# ATSAMD10D13A register map
Vendor: Atmel Corporation; Series: SAMD10; File version: A
CPU: CM0+ r0p1, little endian, no MPU, no FPU, VTOR, 2 interrupt priority bits
Registers are 32-bit, read-write, reset 0x0 unless marked. A register's access mark holds for its fields unless they carry their own. Offsets are from the block's base; [hi:lo] are bit positions; {n}, {i} and the like mark numbered series; 'fields as' and 'values as' point back to an identical list.

## DAC — Digital Analog Converter
Base 0x42002800; register names take the prefix DAC_
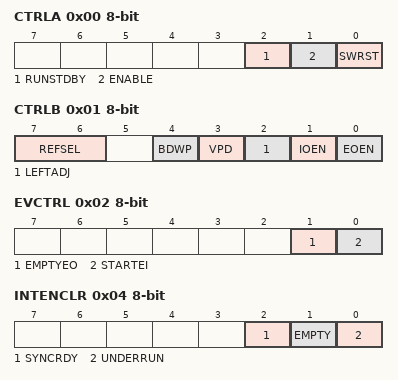
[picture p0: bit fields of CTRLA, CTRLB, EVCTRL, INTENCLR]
0x00 CTRLA 8-bit — Control A
  [2] RUNSTDBY — Run in Standby
  [1] ENABLE
  [0] SWRST — Software Reset
0x01 CTRLB 8-bit — Control B
  [7:6] REFSEL — Reference Selection
    0=INT1V (Internal 1.0V reference); 1=AVCC; 2=VREFP (External reference)
  [4] BDWP — Bypass DATABUF Write Protection
  [3] VPD — Voltage Pump Disable
  [2] LEFTADJ — Left Adjusted Data
  [1] IOEN — Internal Output Enable
  [0] EOEN — External Output Enable
0x02 EVCTRL 8-bit — Event Control
  [1] EMPTYEO — Data Buffer Empty Event Output
  [0] STARTEI — Start Conversion Event Input
0x04 INTENCLR 8-bit — Interrupt Enable Clear
  [2] SYNCRDY — Synchronization Ready Interrupt Enable
  [1] EMPTY — Data Buffer Empty Interrupt Enable
  [0] UNDERRUN — Underrun Interrupt Enable
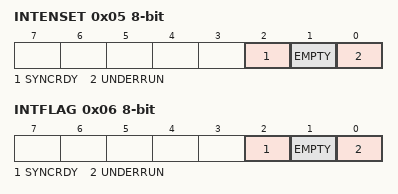
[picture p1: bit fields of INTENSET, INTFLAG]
0x05 INTENSET 8-bit — Interrupt Enable Set
  fields as INTENCLR
0x06 INTFLAG 8-bit — Interrupt Flag Status and Clear
  [2] SYNCRDY — Synchronization Ready
  [1] EMPTY — Data Buffer Empty
  [0] UNDERRUN
0x07 STATUS 8-bit ro
  [7] SYNCBUSY — Synchronization Busy Status
0x08 DATA 16-bit
  [15:0] DATA — Data value to be converted
0x0C DATABUF 16-bit — Data Buffer

## DMAC — Direct Memory Access Controller
Base 0x41004800; register names take the prefix DMAC_
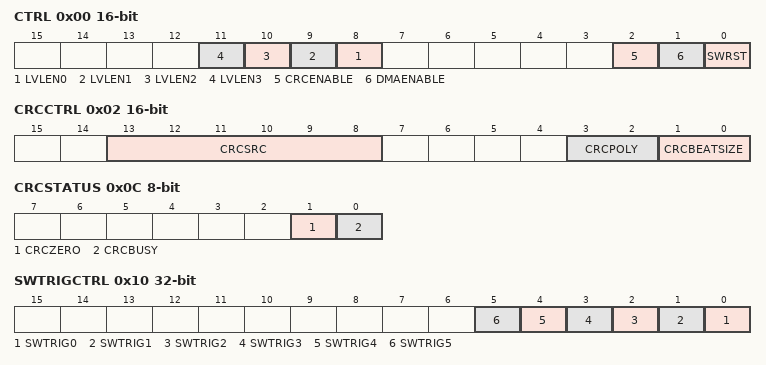
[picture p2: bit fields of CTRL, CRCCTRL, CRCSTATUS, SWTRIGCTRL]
0x00 CTRL 16-bit — Control
  [n+8] LVLEN{n} (n=0..3) — Priority Level {n} Enable
  [2] CRCENABLE
  [1] DMAENABLE
  [0] SWRST — Software Reset
0x02 CRCCTRL 16-bit — CRC Control
  [13:8] CRCSRC — CRC Input Source
    0=NOACT (No action); 1=IO (I/O interface)
  [3:2] CRCPOLY — CRC Polynomial Type
    0=CRC16 (CRC-16 (CRC-CCITT)); 1=CRC32 (CRC32 (IEEE 802.3))
  [1:0] CRCBEATSIZE
    0=BYTE (Byte bus access); 1=HWORD (Half-word bus access); 2=WORD (Word bus access)
0x04 CRCDATAIN — CRC Data Input
0x08 CRCCHKSUM — CRC Checksum
0x0C CRCSTATUS 8-bit
  [1] CRCZERO ro
  [0] CRCBUSY — CRC Module Busy
0x0D DBGCTRL 8-bit — Debug Control
  [0] DBGRUN — Debug Run
0x10 SWTRIGCTRL — Software Trigger Control
  [n] SWTRIG{n} (n=0..5) — Channel {n} Software Trigger
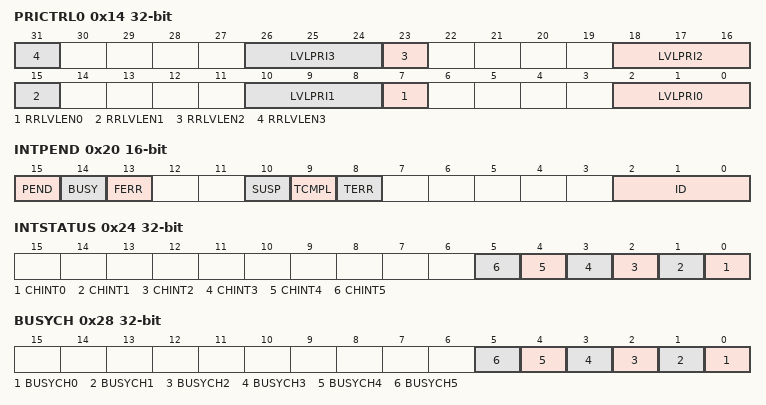
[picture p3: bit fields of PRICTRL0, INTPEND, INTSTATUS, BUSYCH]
0x14 PRICTRL0 — Priority Control 0
  [8n+7] RRLVLEN{n} (n=0..3) — Level {n} Round-Robin Scheduling Enable
  [8n+2:8n] LVLPRI{n} (n=0..3) — Level {n} Channel Priority Number
0x20 INTPEND 16-bit — Interrupt Pending
  [15] PEND ro — Pending
  [14] BUSY ro
  [13] FERR ro — Fetch Error
  [10] SUSP — Channel Suspend
  [9] TCMPL — Transfer Complete
  [8] TERR — Transfer Error
  [2:0] ID — Channel ID
0x24 INTSTATUS ro — Interrupt Status
  [n] CHINT{n} (n=0..5) — Channel {n} Pending Interrupt
0x28 BUSYCH ro — Busy Channels
  [n] BUSYCH{n} (n=0..5) — Busy Channel {n}
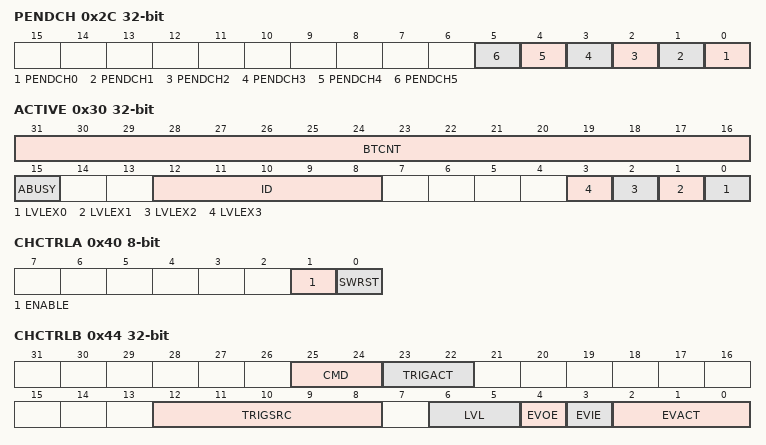
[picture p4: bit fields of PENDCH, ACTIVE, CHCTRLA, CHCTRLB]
0x2C PENDCH ro — Pending Channels
  [n] PENDCH{n} (n=0..5) — Pending Channel {n}
0x30 ACTIVE ro — Active Channel and Levels
  [31:16] BTCNT — Active Channel Block Transfer Count
  [15] ABUSY — Active Channel Busy
  [12:8] ID — Active Channel ID
  [n] LVLEX{n} (n=0..3) — Level {n} Channel Trigger Request Executing
0x34 BASEADDR — Descriptor Memory Section Base Address
  [31:0] BASEADDR — Descriptor Memory Base Address
0x38 WRBADDR — Write-Back Memory Section Base Address
  [31:0] WRBADDR — Write-Back Memory Base Address
0x3F CHID 8-bit — Channel ID
  [2:0] ID
0x40 CHCTRLA 8-bit — Channel Control A
  [1] ENABLE — Channel Enable
  [0] SWRST — Channel Software Reset
0x44 CHCTRLB — Channel Control B
  [25:24] CMD — Software Command
    0=NOACT (No action); 1=SUSPEND (Channel suspend operation); 2=RESUME (Channel resume operation)
  [23:22] TRIGACT — Trigger Action
    0=BLOCK (One trigger required for each block transfer); 2=BEAT (One trigger required for each beat transfer); 3=TRANSACTION (One trigger required for each transaction)
  [12:8] TRIGSRC — Peripheral Trigger Source
    0=DISABLE (Only software/event triggers)
  [6:5] LVL — Channel Arbitration Level
  [4] EVOE — Channel Event Output Enable
  [3] EVIE — Channel Event Input Enable
  [2:0] EVACT — Event Input Action
    0=NOACT (No action); 1=TRIG (Transfer and periodic transfer trigger); 2=CTRIG (Conditional transfer trigger); 3=CBLOCK (Conditional block transfer); 4=SUSPEND (Channel suspend operation); 5=RESUME (Channel resume operation); 6=SSKIP (Skip next block suspend action)
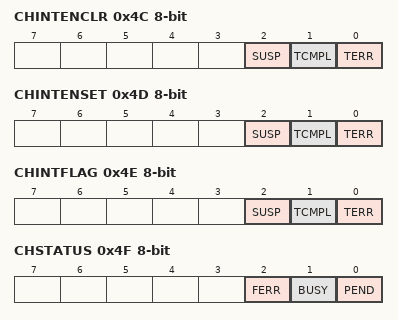
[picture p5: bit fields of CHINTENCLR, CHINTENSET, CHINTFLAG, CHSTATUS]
0x4C CHINTENCLR 8-bit — Channel Interrupt Enable Clear
  [2] SUSP — Channel Suspend Interrupt Enable
  [1] TCMPL — Transfer Complete Interrupt Enable
  [0] TERR — Transfer Error Interrupt Enable
0x4D CHINTENSET 8-bit — Channel Interrupt Enable Set
  fields as CHINTENCLR
0x4E CHINTFLAG 8-bit — Channel Interrupt Flag Status and Clear
  [2] SUSP — Channel Suspend
  [1] TCMPL — Transfer Complete
  [0] TERR — Transfer Error
0x4F CHSTATUS 8-bit ro — Channel Status
  [2] FERR — Fetch Error
  [1] BUSY — Channel Busy
  [0] PEND — Channel Pending

## Notices in the file
Atmel Microcontroller Software Support
Copyright (c) 2014, Atmel Corporation
All rights reserved.
Redistribution and use in source and binary forms, with or without
modification, are permitted provided that the following condition is met:
- Redistributions of source code must retain the above copyright notice,
this list of conditions and the disclaimer below.
Atmel's name may not be used to endorse or promote products derived from
this software without specific prior written permission.
DISCLAIMER: THIS SOFTWARE IS PROVIDED BY ATMEL "AS IS" AND ANY EXPRESS OR
IMPLIED WARRANTIES, INCLUDING, BUT NOT LIMITED TO, THE IMPLIED WARRANTIES OF
MERCHANTABILITY, FITNESS FOR A PARTICULAR PURPOSE AND NON-INFRINGEMENT ARE
DISCLAIMED. IN NO EVENT SHALL ATMEL BE LIABLE FOR ANY DIRECT, INDIRECT,
INCIDENTAL, SPECIAL, EXEMPLARY, OR CONSEQUENTIAL DAMAGES (INCLUDING, BUT NOT
LIMITED TO, PROCUREMENT OF SUBSTITUTE GOODS OR SERVICES; LOSS OF USE, DATA,
OR PROFITS; OR BUSINESS INTERRUPTION) HOWEVER CAUSED AND ON ANY THEORY OF
LIABILITY, WHETHER IN CONTRACT, STRICT LIABILITY, OR TORT (INCLUDING
NEGLIGENCE OR OTHERWISE) ARISING IN ANY WAY OUT OF THE USE OF THIS SOFTWARE,
EVEN IF ADVISED OF THE POSSIBILITY OF SUCH DAMAGE.
